# M073 register map
File version: 2.0.2.4
Registers are 32-bit, read-write, reset 0x0 unless marked. A register's access mark holds for its fields unless they carry their own. Offsets are from the block's base; [hi:lo] are bit positions; {n}, {i} and the like mark numbered series.

## VE — Vector Engine (VE)
Base 0x400F8000
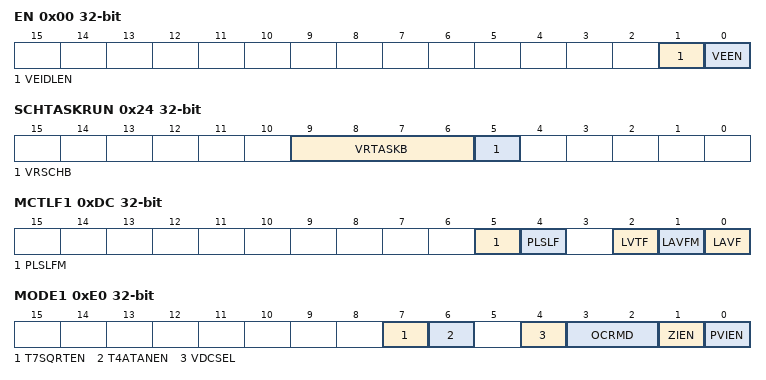
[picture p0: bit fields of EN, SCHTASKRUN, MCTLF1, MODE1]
0x00 EN — VE enable_disable
  [1] VEIDLEN, [0] VEEN
0x04 CPURUNTRG wo — CPU start trigger selection
  [1] VCPURTB
0x08 TASKAPP — Task selection
  [7:4] VTASKB
0x0C ACTSCH — Operation schedule selection
  [7:4] VACTB
0x10 REPTIME — Schedule repeat count
  [7:4] VREPB
0x14 TRGMODE — Start trigger mode
  [3:2] VTRGB
0x18 ERRINTEN — Error interrupt enable_disable
  [1] VERRENB
0x1C COMPEND wo — VE forced termination
  [1] VCENDB
0x20 ERRDET ro — Error detection
  [1] VERRDB
0x24 SCHTASKRUN ro — Schedule executing flag_executing task
  [9:6] VRTASKB, [5] VRSCHB
{0x2C+4i} TMPREG{i} (i=0..5) — Temporary register
0xDC MCTLF1 — Status flags
  [5] PLSLFM, [4] PLSLF, [2] LVTF, [1] LAVFM, [0] LAVF
0xE0 MODE1 — Task control mode
  [7] T7SQRTEN, [6] T4ATANEN, [4] VDCSEL, [3:2] OCRMD, [1] ZIEN, [0] PVIEN
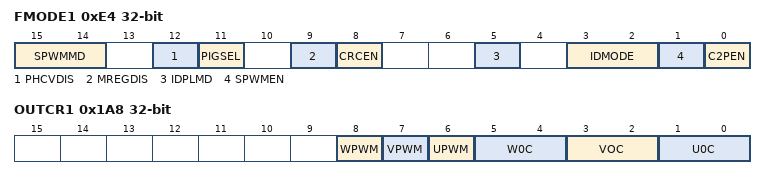
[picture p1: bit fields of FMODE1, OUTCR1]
0xE4 FMODE1 — Flow control
  [15:14] SPWMMD, [12] PHCVDIS, [11] PIGSEL, [9] MREGDIS, [8] CRCEN, [5] IDPLMD, [3:2] IDMODE, [1] SPWMEN, [0] C2PEN
0xE8 TPWM1 — PWM period rate (PWM period _s_* maximum speed * 2^16) setting
  [15:0] TPWM
0xEC OMEGA1 — Rotation speed (speed _Hz_ _ maximum speed * 2^15) setting
  [15:0] OMEGA
0xF0 THETA1 — Motor phase (motor phase _deg_ _ 360 * 2^16) setting
  [15:0] THETA
0xF4 IDREF1 — d-axis reference value (current _A_ _ maximum current * 2^15)
  [15:0] IDREF
0xF8 IQREF1 — q-axis reference value (current _A_ _ maximum current * 2^15)
  [15:0] IQREF
0xFC VD1 — d-axis voltage (voltage _V_ _ maximum voltage * 2^31)
  [31:0] VD
0x100 VQ1 — q-axis voltage (voltage _V_ _ maximum voltage * 2^31)
  [31:0] VQ
0x104 CIDKI1 — Integral coefficient for PI control of d-axis
  [15:0] CIDKI
0x108 CIDKP1 — Proportional coefficient for PI control of d-axis
  [15:0] CIDKP
0x10C CIQKI1 — Integral coefficient for PI control of q-axis
  [15:0] CIQKI
0x110 CIQKP1 — Proportional coefficient for PI control of q-axis
  [15:0] CIQKP
0x114 VDIH1 — Upper 32 bits of integral term (VDI) of d-axis voltage
  [31:0] VDIH
0x118 VDILH1 — Lower 32 bits of integral term (VDI) of d-axis voltage
  [31:16] VDILH
0x11C VQIH1 — Upper 32 bits of integral term (VQI) of q-axis voltage
  [31:0] VQIH
0x120 VQILH1 — Lower 32 bits of integral term (VQI) of q-axis voltage
  [31:16] VQILH
0x124 FPWMCHG1 — Switching speed (for 2-phase modulation and shift PWM)
  [15:0] FPWMCHG
0x128 MDPRD1 — PWM period (to be set identically with PMD's PWM period)
  [15:0] VMDPRD
0x12C MINPLS1 — Minimum pulse width
  [15:0] MINPLS
0x130 TRGCRC1 — Synchronizing trigger correction value
  [15:0] TRGCRC
0x134 VDCL1 — Cosine value at THETA for output conversion (Q15 data)
  [15:0] VDCL
0x138 COS1 — Cosine value at THETA for output conversion (Q15 data)
  [15:0] COS
0x13C SIN1 — Sine value at THETA for output conversion (Q15 data)
  [15:0] SIN
0x140 COSM1 — Previous cosine value for input processing (Q15 data)
  [15:0] COSM
0x144 SINM1 — Previous sine value for input processing (Q15 data)
  [15:0] SINM
0x148 SECTOR1 — Sector information (0-11)
  [3:0] SECTOR
0x14C SECTORM1 — Previous sector information for input processing (0-11)
  [3:0] SECTORM
0x150 IAO1 — AD conversion result of a-phase zero-current
  [15:0] IAO
0x154 IBO1 — AD conversion result of b-phase zero-current
  [15:0] IB0
0x158 ICO1 — AD conversion result of c-phase zero-current
  [15:0] IC0
0x15C IAADC1 — AD conversion result of a-phase current
  [15:0] IAADC
0x160 IBADC1 — AD conversion result of b-phase current
  [15:0] IBADC
0x164 ICADC1 — AD conversion result of c-phase current
  [15:0] ICADC
0x168 VDC1 — DC supply voltage (voltage _V_ _ maximum voltage * 2^15)
  [15:0] VDC
0x16C ID1 — d-axis current (current _A_ _ maximum current * 2^31)
  [31:0] ID
0x170 IQ1 — q-axis current (current _A_ _ maximum current * 2^31)
  [31:0] IQ
0x178 TADC — ADC start wait setting
  [15:0] TADC
0x19C CMPU1 — PMD control_ CMPU setting
  [15:0] VCMPU
0x1A0 CMPV1 — PMD control_ CMPV setting
  [15:0] VCMPV
0x1A4 CMPW1 — PMD control_ CMPW setting
  [15:0] VCMPW
0x1A8 OUTCR1 — PMD control_ Output control (MDOUT)
  [8] WPWM, [7] VPWM, [6] UPWM, [5:4] W0C, [3:2] VOC, [1:0] U0C
0x1AC TRGCMP01 — PMD control_ TRGCMP0 setting
  [15:0] VTRGCMP0
0x1B0 TRGCMP11 — PMD control_ TRGCMP1 setting
  [15:0] VTRGCMP1
0x1B4 TRGSEL1 — PMD control_ Trigger selection
  [2:0] VTRGSEL
0x1B8 EMGRS1 — PMD control_ EMG return (EMGCR_EMGRS_)
  [0] EMGRS
